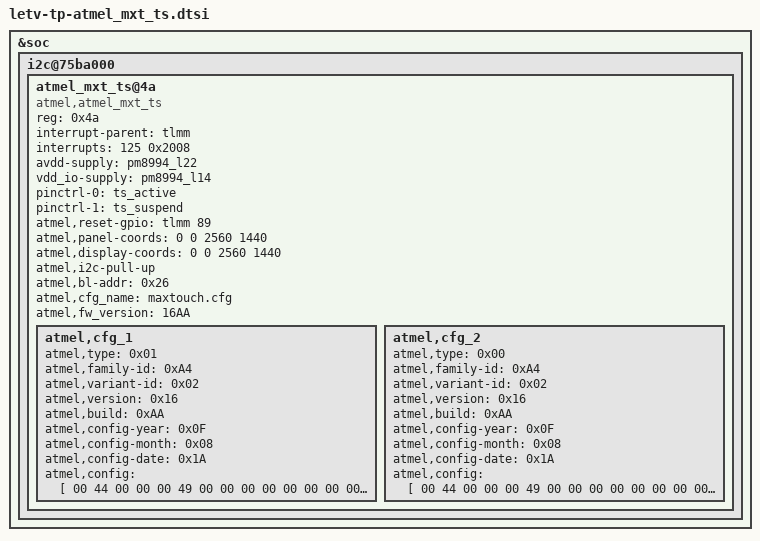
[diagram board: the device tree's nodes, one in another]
&soc {
	i2c@75ba000 {
		atmel_mxt_ts@4a {
			compatible = "atmel,atmel_mxt_ts";
			reg = <0x4a>;
			interrupt-parent = <&tlmm>;
			interrupts = <125 0x2008>;
			avdd-supply = <&pm8994_l22>;
			vdd_io-supply = <&pm8994_l14>;
			pinctrl-names = "pmx_ts_active", "pmx_ts_suspend";
			pinctrl-0 = <&ts_active>;
			pinctrl-1 = <&ts_suspend>;
			atmel,reset-gpio = <&tlmm 89 0>;
			atmel,panel-coords = <0 0 2560 1440>;
			atmel,display-coords = <0 0 2560 1440>;
			atmel,i2c-pull-up;
			atmel,bl-addr = <0x26>;
			atmel,cfg_name = "maxtouch.cfg";
			atmel,fw_version = "16AA";
			status = "ok";
			atmel,cfg_1 {
				atmel,type = <0x01>;
				atmel,family-id = <0xA4>;
				atmel,variant-id = <0x02>;
				atmel,version = <0x16>;
				atmel,build = <0xAA>;
				atmel,config-year = <0x0F>;
				atmel,config-month = <0x08>;
				atmel,config-date = <0x1A>;
				atmel,config = [
					00 44 00 00 00 49 00 00
					00 00 00 00 00 00 00 00
					00 00 00 00 00 00 00 00
					00 00 00 00 00 00 00 00
					00 00 00 00 00 00 00 00
					00 00 00 00 00 00 00 00
					00 00 00 00 00 00 00 00
					00 00 00 00 00 00 00 00
					00 00 00 00 00 00 00 00
					00 00 00 00 00 00 00
					00 26 00 00 00 40 01 16
					AA 0F 08 1A 00 00 00 00
					00 00 00 00 00 00 00 00
					00 00 00 00 00 00 00 00
					00 00 00 00 00 00 00 00
					00 00 00 00 00 00 00 00
					00 00 00 00 00 00 00 00
					00 00 00 00 00 00 00 00
					00 00 00 00 00 00
					00 47 00 00 00 C8 11 10
					01 01 01 FF 1E 00 00 00
					00 00 00 00 00 00 00 00
					00 00 00 00 00 00 00 00
					00 00 00 00 00 00 00 00
					00 00 00 00 00 00 00 00
					00 00 00 00 00 00 00 00
					00 00 00 00 00 00 00 00
					00 00 00 00 00 00 00 00
					00 00 00 00 00 00 00 00
					00 00 00 00 00 00 00 00
					00 00 00 00 00 00 00 00
					00 00 00 00 00 00 00 00
					00 00 00 00 00 00 00 00
					00 00 00 00 00 00 00 00
					00 00 00 00 00 00 00 00
					00 00 00 00 00 00 00 00
					00 00 00 00 00 00 00 00
					00 00 00 00 00 00 00 00
					00 00 00 00 00 00 00 00
					00 00 00 00 00 00 00 00
					00 00 00 00 00 00 00 00
					00 00 00 00 00 00 00 00
					00 00 00 00 00 00 00 00
					00 00 00 00 00 00 00 00
					00 00 00 00 00 00
					00 6E 00 00 00 28 01 00
					11 03 41 04 51 04 79 02
					B1 05 C1 07 81 08 31 09
					49 07 19 0B 89 0B F9 0A
					01 00 01 00 01 00 01 00
					01 00 01 00 01 00
					00 6E 00 01 00 28 01 00
					01 00 B1 03 89 06 19 07
					E1 09 C9 0D F9 0F 39 01
					F1 00 51 09 81 0B 11 0F
					01 00 01 00 01 00 01 00
					01 00 01 00 01 00
					00 6E 00 02 00 28 01 00
					01 00 01 00 01 00 01 00
					01 00 01 00 29 00 C1 02
					B1 00 31 0C F9 0F 19 0F
					01 00 01 00 01 00 01 00
					01 00 01 00 01 00
					00 6E 00 03 00 28 01 00
					11 03 41 04 51 04 79 02
					B1 05 C1 07 81 08 31 09
					49 07 19 0B 89 0B F9 0A
					01 00 01 00 01 00 01 00
					01 00 01 00 01 00
					00 6E 00 04 00 28 01 00
					01 00 B1 03 89 06 19 07
					E1 09 C9 0D F9 0F 39 01
					F1 00 51 09 81 0B 11 0F
					01 00 01 00 01 00 01 00
					01 00 01 00 01 00
					00 6E 00 05 00 28 01 00
					01 00 01 00 01 00 01 00
					01 00 01 00 29 00 C1 02
					B1 00 31 0C F9 0F 19 0F
					01 00 01 00 01 00 01 00
					01 00 01 00 01 00
					00 6E 00 06 00 28 43 03
					2B 03 2B 03 1B 03 2B 03
					13 03 03 03 F3 02 F3 02
					EB 02 E3 02 E3 02 F3 02
					03 00 03 00 03 00 03 00
					03 00 03 00 03 00
					00 6E 00 07 00 28 03 00
					CB 0F CB 0F CB 0F CB 0F
					CB 0F CB 0F CB 0F CB 0F
					CB 0F CB 0F CB 0F CB 0F
					03 00 03 00 03 00 03 00
					03 00 03 00 03 00
					00 6E 00 08 00 28 03 00
					CB 0F CB 0F CB 0F CB 0F
					CB 0F CB 0F CB 0F CB 0F
					CB 0F CB 0F CB 0F CB 0F
					03 00 03 00 03 00 03 00
					03 00 03 00 03 00
					00 07 00 00 00 05 FF FF
					19 40 00
					00 08 00 00 00 0F 8C 00
					0F 03 00 00 00 00 14 0F
					09 21 21 01 00
					00 0F 00 00 00 0B 00 1C
					10 01 03 00 05 2D 00 00
					00
					00 12 00 00 00 02 40 00
					00 13 00 00 00 06 00 00
					00 00 00 00
					00 19 00 00 00 10 00 00
					00 00 00 00 00 00 00 00
					00 00 00 00 00 00
					00 28 00 00 00 05 10 00
					00 19 19
					00 2A 00 00 00 0D 21 01
					3C 1B FF 64 00 5F 00 00
					11 03 00
					00 2B 00 00 00 12 00 00
					00 00 00 00 00 00 00 00
					00 00 00 00 00 00 00 00
					00 2E 00 00 00 0C 00 00
					10 10 00 00 00 00 00 01
					00 00
					00 2F 00 00 00 28 08 00
					23 FF 04 16 14 B9 01 18
					20 10 00 00 00 00 00 00
					00 00 00 00 80 00 80 00
					00 00 00 00 00 00 00 00
					00 00 00 00 00 00
					00 38 00 00 00 24 01 00
					01 78 0E 0D 0C 0C 0B 0A
					08 06 06 04 03 03 03 03
					02 02 02 02 02 02 02 02
					02 01 01 01 00 00 00 00
					00 00
					00 3D 00 00 00 05 01 00
					00 D0 07
					00 3D 00 01 00 05 02 00
					00 98 3A
					00 3D 00 02 00 05 02 00
					00 50 C3
					00 3D 00 03 00 05 02 00
					00 10 27
					00 3D 00 04 00 05 02 00
					00 E8 03
					00 3D 00 05 00 05 02 00
					00 10 27
					00 41 00 00 00 17 81 1E
					00 00 00 00 00 00 00 00
					0A 00 00 00 00 00 00 21
					00 00 00 00 00
					00 41 00 01 00 17 00 00
					00 00 00 00 00 00 00 00
					00 00 00 00 00 00 00 21
					00 00 00 00 00
					00 41 00 02 00 17 00 00
					00 00 00 00 00 00 00 00
					00 00 00 00 00 00 00 00
					00 00 00 00 00
					00 46 00 00 00 0A 03 26
					00 28 00 00 00 00 00 00
					00 46 00 01 00 0A 03 27
					00 28 00 00 00 01 00 00
					00 46 00 02 00 0A 01 0A
					00 3D 00 00 01 02 00 00
					00 46 00 03 00 0A 00 0D
					00 46 00 05 00 03 00 00
					00 46 00 04 00 0A 00 0D
					00 46 00 06 00 04 00 00
					00 46 00 05 00 0A 01 0D
					00 6F 00 00 15 05 00 00
					00 46 00 06 00 0A 01 0B
					00 6F 00 00 15 06 00 00
					00 46 00 07 00 0A 00 00
					00 00 00 00 00 00 00 00
					00 46 00 08 00 0A 00 00
					00 00 00 00 00 00 00 00
					00 46 00 09 00 0A 00 00
					00 00 00 00 00 00 00 00
					00 46 00 0A 00 0A 00 00
					00 00 00 00 00 00 00 00
					00 46 00 0B 00 0A 00 00
					00 00 00 00 00 00 00 00
					00 46 00 0C 00 0A 00 00
					00 00 00 00 00 00 00 00
					00 46 00 0D 00 0A 00 00
					00 00 00 00 00 00 00 00
					00 46 00 0E 00 0A 00 00
					00 00 00 00 00 00 00 00
					00 46 00 0F 00 0A 00 00
					00 00 00 00 00 00 00 00
					00 46 00 10 00 0A 00 00
					00 00 00 00 00 00 00 00
					00 46 00 11 00 0A 00 00
					00 00 00 00 00 00 00 00
					00 46 00 12 00 0A 00 00
					00 00 00 00 00 00 00 00
					00 46 00 13 00 0A 00 00
					00 00 00 00 00 00 00 00
					00 48 00 00 00 55 01 00
					00 01 00 05 0A 0A 00 06
					0C 18 02 04 20 00 0D 09
					36 05 00 01 0C 1C 27 31
					1C 1C 1C 1C 1C 1C 1C 1C
					1C 1C 00 00 16 22 01 01
					0C 1C 27 31 40 40 40 40
					40 40 40 40 40 40 00 0E
					1E 50 0F 01 0C 1C 27 31
					40 40 40 40 40 40 40 40
					40 40 00 16 00 50 00 03
					08 02 02
					00 4D 00 00 00 02 00 00
					00 4E 00 00 00 0C 84 05
					05 02 14 02 18 00 00 0F
					03 0A
					00 4F 00 00 00 04 01 0A
					00 02
					00 4F 00 01 00 04 00 00
					00 00
					00 4F 00 02 00 04 00 00
					00 00
					00 50 00 00 00 0C 08 28
					C8 1F 04 E4 03 00 00 00
					00 00
					00 51 00 00 00 12 02 00
					00 19 E6 E1 19 19 C8 E1
					19 02 FF 00 00 01 00 00
					00 51 00 01 00 12 00 00
					00 00 00 00 00 00 00 00
					00 00 00 00 00 00 00 00
					00 54 00 00 00 04 00 00
					00 00
					00 5D 00 00 00 1E 0D 3C
					00 FF FF 3C 00 FF FF FF
					0F FF 0F 00 14 00 14 04
					00 00 C8 00 C8 00 00 20
					00 20 00 00
					00 63 00 00 00 0C 00 00
					00 00 00 00 00 00 00 00
					00 00
					00 64 00 00 00 3C 83 32
					07 10 00 00 0A 88 00 18
					35 0F 0A FF 09 32 1E 32
					3C 00 0D 35 02 02 9F 05
					31 33 0A 06 37 0A 14 00
					00 37 3C 0A 00 01 01 00
					00 0A 44 FA 41 1E 00 08
					00 00 00 00 BF 19 B2 3C
					B1 32
					00 65 00 00 00 1E 00 00
					00 00 00 18 10 03 00 00
					00 00 18 0F 03 04 01 02
					FA 0A 19 00 0A 00 00 28
					00 00 00 00
					00 68 00 00 00 0B 01 09
					2D 0F 0A 03 09 2D 0F 0A
					03
					00 6C 00 00 00 4B 00 00
					00 00 00 00 00 00 00 00
					00 00 00 00 00 00 00 00
					00 00 00 00 00 00 00 00
					00 00 00 00 00 00 00 00
					00 00 00 00 00 00 00 00
					00 00 00 00 00 00 00 00
					00 00 00 00 00 00 00 00
					00 00 00 00 00 00 00 00
					00 00 00 00 00 00 00 00
					00
					00 6D 00 00 00 09 00 00
					05 00 00 00 00 00 00
					00 6F 00 00 00 17 08 00
					28 5C 28 28 08 0A 00 1E
					00 00 00 00 00 00 00 00
					00 00 33 1E 28
					00 6F 00 01 00 17 0C 00
					5F 5C 80 80 11 03 00 FF
					7F 32 11 08 0A 00 00 00
					00 00 00 00 00
					00 6F 00 02 00 17 00 00
					28 40 20 20 14 00 00 1F
					0F 22 01 01 01 00 00 00
					00 00 00 FF 00
					00 70 00 00 00 05 00 00
					00 00 00
					00 70 00 01 00 05 00 00
					00 00 00
					00 71 00 00 00 03 05 05
					05
					00 73 00 00 00 14 85 00
					00 FF FF 00 00 FF FF 35
					00 43 00 02 3E 02 00 88
					55 11
					00 74 00 00 00 FF 00 03
					03 00 D5 66 02 03 03 00
					D6 55 02 03 0C 00 D7 33
					02 13 0C 00 D8 44 02 42
					03 70 55 26 42 03 70 56
					25 12 0C 07 57 23 12 0C
					07 58 24 02 00 00 5A 22
					00 00 00 00 00 00 00 00
					00 00 00 00 00 00 00 00
					00 00 00 00 00 00 00 00
					00 00 00 00 00 00 00 00
					00 00 00 00 00 00 00 00
					00 00 00 00 00 00 00 00
					00 00 00 00 00 00 00 00
					00 00 00 00 00 00 00 00
					00 00 00 00 00 00 00 00
					00 00 00 00 00 00 00 00
					00 00 00 00 00 00 00 00
					00 00 00 00 00 00 00 00
					00 00 00 00 00 00 00 00
					00 00 00 00 00 00 00 00
					00 00 00 00 00 00 00 00
					00 00 00 00 00 00 00 00
					00 00 00 00 00 00 00 00
					00 00 00 00 00 00 00 00
					00 00 00 00 00 00 00 00
					00 00 00 00 00 00 00 00
					00 00 00 00 00 00 00 00
					00 00 00 00 00 00 00 00
					00 00 00 00 00 00 00 00
					00 00 00 00 00 00 00 00
					00 00 00 00 00 00 00 00
					00 00 00 00 00
					00 79 00 00 00 03 00 03
					00
				];
			};
			atmel,cfg_2 {
				atmel,type = <0x00>;
				atmel,family-id = <0xA4>;
				atmel,variant-id = <0x02>;
				atmel,version = <0x16>;
				atmel,build = <0xAA>;
				atmel,config-year = <0x0F>;
				atmel,config-month = <0x08>;
				atmel,config-date = <0x1A>;
				atmel,config = [
					00 44 00 00 00 49 00 00
					00 00 00 00 00 00 00 00
					00 00 00 00 00 00 00 00
					00 00 00 00 00 00 00 00
					00 00 00 00 00 00 00 00
					00 00 00 00 00 00 00 00
					00 00 00 00 00 00 00 00
					00 00 00 00 00 00 00 00
					00 00 00 00 00 00 00 00
					00 00 00 00 00 00 00
					00 26 00 00 00 40 01 16
					AA 0F 08 1A 00 00 00 00
					00 00 00 00 00 00 00 00
					00 00 00 00 00 00 00 00
					00 00 00 00 00 00 00 00
					00 00 00 00 00 00 00 00
					00 00 00 00 00 00 00 00
					00 00 00 00 00 00 00 00
					00 00 00 00 00 00
					00 47 00 00 00 C8 11 10
					01 01 01 FF 1E 00 00 00
					00 00 00 00 00 00 00 00
					00 00 00 00 00 00 00 00
					00 00 00 00 00 00 00 00
					00 00 00 00 00 00 00 00
					00 00 00 00 00 00 00 00
					00 00 00 00 00 00 00 00
					00 00 00 00 00 00 00 00
					00 00 00 00 00 00 00 00
					00 00 00 00 00 00 00 00
					00 00 00 00 00 00 00 00
					00 00 00 00 00 00 00 00
					00 00 00 00 00 00 00 00
					00 00 00 00 00 00 00 00
					00 00 00 00 00 00 00 00
					00 00 00 00 00 00 00 00
					00 00 00 00 00 00 00 00
					00 00 00 00 00 00 00 00
					00 00 00 00 00 00 00 00
					00 00 00 00 00 00 00 00
					00 00 00 00 00 00 00 00
					00 00 00 00 00 00 00 00
					00 00 00 00 00 00 00 00
					00 00 00 00 00 00 00 00
					00 00 00 00 00 00
					00 6E 00 00 00 28 01 00
					11 03 41 04 51 04 79 02
					B1 05 C1 07 81 08 31 09
					49 07 19 0B 89 0B F9 0A
					01 00 01 00 01 00 01 00
					01 00 01 00 01 00
					00 6E 00 01 00 28 01 00
					01 00 B1 03 89 06 19 07
					E1 09 C9 0D F9 0F 39 01
					F1 00 51 09 81 0B 11 0F
					01 00 01 00 01 00 01 00
					01 00 01 00 01 00
					00 6E 00 02 00 28 01 00
					01 00 01 00 01 00 01 00
					01 00 01 00 29 00 C1 02
					B1 00 31 0C F9 0F 19 0F
					01 00 01 00 01 00 01 00
					01 00 01 00 01 00
					00 6E 00 03 00 28 01 00
					11 03 41 04 51 04 79 02
					B1 05 C1 07 81 08 31 09
					49 07 19 0B 89 0B F9 0A
					01 00 01 00 01 00 01 00
					01 00 01 00 01 00
					00 6E 00 04 00 28 01 00
					01 00 B1 03 89 06 19 07
					E1 09 C9 0D F9 0F 39 01
					F1 00 51 09 81 0B 11 0F
					01 00 01 00 01 00 01 00
					01 00 01 00 01 00
					00 6E 00 05 00 28 01 00
					01 00 01 00 01 00 01 00
					01 00 01 00 29 00 C1 02
					B1 00 31 0C F9 0F 19 0F
					01 00 01 00 01 00 01 00
					01 00 01 00 01 00
					00 6E 00 06 00 28 43 03
					2B 03 2B 03 1B 03 2B 03
					13 03 03 03 F3 02 F3 02
					EB 02 E3 02 E3 02 F3 02
					03 00 03 00 03 00 03 00
					03 00 03 00 03 00
					00 6E 00 07 00 28 03 00
					CB 0F CB 0F CB 0F CB 0F
					CB 0F CB 0F CB 0F CB 0F
					CB 0F CB 0F CB 0F CB 0F
					03 00 03 00 03 00 03 00
					03 00 03 00 03 00
					00 6E 00 08 00 28 03 00
					CB 0F CB 0F CB 0F CB 0F
					CB 0F CB 0F CB 0F CB 0F
					CB 0F CB 0F CB 0F CB 0F
					03 00 03 00 03 00 03 00
					03 00 03 00 03 00
					00 07 00 00 00 05 FF FF
					19 40 00
					00 08 00 00 00 0F 8C 00
					0F 03 00 00 00 00 14 0F
					09 21 21 01 00
					00 0F 00 00 00 0B 00 1C
					10 01 03 00 05 2D 00 00
					00
					00 12 00 00 00 02 40 00
					00 13 00 00 00 06 00 00
					00 00 00 00
					00 19 00 00 00 10 00 00
					00 00 00 00 00 00 00 00
					00 00 00 00 00 00
					00 28 00 00 00 05 10 00
					00 19 19
					00 2A 00 00 00 0D 21 01
					3C 1B FF 64 00 5F 00 00
					11 03 00
					00 2B 00 00 00 12 00 00
					00 00 00 00 00 00 00 00
					00 00 00 00 00 00 00 00
					00 2E 00 00 00 0C 00 00
					10 10 00 00 00 00 00 01
					00 00
					00 2F 00 00 00 28 08 00
					23 FF 04 16 14 B9 01 18
					20 10 00 00 00 00 00 00
					00 00 00 00 80 00 80 00
					00 00 00 00 00 00 00 00
					00 00 00 00 00 00
					00 38 00 00 00 24 01 00
					01 78 0E 0D 0C 0C 0B 0A
					08 06 06 04 03 03 03 03
					02 02 02 02 02 02 02 02
					02 01 01 01 00 00 00 00
					00 00
					00 3D 00 00 00 05 01 00
					00 D0 07
					00 3D 00 01 00 05 02 00
					00 98 3A
					00 3D 00 02 00 05 02 00
					00 50 C3
					00 3D 00 03 00 05 02 00
					00 10 27
					00 3D 00 04 00 05 02 00
					00 E8 03
					00 3D 00 05 00 05 02 00
					00 10 27
					00 41 00 00 00 17 81 1E
					00 00 00 00 00 00 00 00
					0A 00 00 00 00 00 00 21
					00 00 00 00 00
					00 41 00 01 00 17 00 00
					00 00 00 00 00 00 00 00
					00 00 00 00 00 00 00 21
					00 00 00 00 00
					00 41 00 02 00 17 00 00
					00 00 00 00 00 00 00 00
					00 00 00 00 00 00 00 00
					00 00 00 00 00
					00 46 00 00 00 0A 03 26
					00 28 00 00 00 00 00 00
					00 46 00 01 00 0A 03 27
					00 28 00 00 00 01 00 00
					00 46 00 02 00 0A 01 0A
					00 3D 00 00 01 02 00 00
					00 46 00 03 00 0A 00 0D
					00 46 00 05 00 03 00 00
					00 46 00 04 00 0A 00 0D
					00 46 00 06 00 04 00 00
					00 46 00 05 00 0A 01 0D
					00 6F 00 00 15 05 00 00
					00 46 00 06 00 0A 01 0B
					00 6F 00 00 15 06 00 00
					00 46 00 07 00 0A 00 00
					00 00 00 00 00 00 00 00
					00 46 00 08 00 0A 00 00
					00 00 00 00 00 00 00 00
					00 46 00 09 00 0A 00 00
					00 00 00 00 00 00 00 00
					00 46 00 0A 00 0A 00 00
					00 00 00 00 00 00 00 00
					00 46 00 0B 00 0A 00 00
					00 00 00 00 00 00 00 00
					00 46 00 0C 00 0A 00 00
					00 00 00 00 00 00 00 00
					00 46 00 0D 00 0A 00 00
					00 00 00 00 00 00 00 00
					00 46 00 0E 00 0A 00 00
					00 00 00 00 00 00 00 00
					00 46 00 0F 00 0A 00 00
					00 00 00 00 00 00 00 00
					00 46 00 10 00 0A 00 00
					00 00 00 00 00 00 00 00
					00 46 00 11 00 0A 00 00
					00 00 00 00 00 00 00 00
					00 46 00 12 00 0A 00 00
					00 00 00 00 00 00 00 00
					00 46 00 13 00 0A 00 00
					00 00 00 00 00 00 00 00
					00 48 00 00 00 55 01 00
					00 01 00 05 0A 0A 00 06
					0C 18 02 04 20 00 0D 09
					36 05 00 01 0C 1C 27 31
					1C 1C 1C 1C 1C 1C 1C 1C
					1C 1C 00 00 16 22 01 01
					0C 1C 27 31 40 40 40 40
					40 40 40 40 40 40 00 0E
					1E 50 0F 01 0C 1C 27 31
					40 40 40 40 40 40 40 40
					40 40 00 16 00 50 00 03
					08 02 02
					00 4D 00 00 00 02 00 00
					00 4E 00 00 00 0C 84 05
					05 02 14 02 18 00 00 0F
					03 0A
					00 4F 00 00 00 04 01 0A
					00 02
					00 4F 00 01 00 04 00 00
					00 00
					00 4F 00 02 00 04 00 00
					00 00
					00 50 00 00 00 0C 08 28
					C8 1F 04 E4 03 00 00 00
					00 00
					00 51 00 00 00 12 02 00
					00 19 E6 E1 19 19 C8 E1
					19 02 FF 00 00 01 00 00
					00 51 00 01 00 12 00 00
					00 00 00 00 00 00 00 00
					00 00 00 00 00 00 00 00
					00 54 00 00 00 04 00 00
					00 00
					00 5D 00 00 00 1E 0D 3C
					00 FF FF 3C 00 FF FF FF
					0F FF 0F 00 14 00 14 04
					00 00 C8 00 C8 00 00 20
					00 20 00 00
					00 63 00 00 00 0C 00 00
					00 00 00 00 00 00 00 00
					00 00
					00 64 00 00 00 3C 83 32
					07 10 00 00 0A 88 00 18
					35 0F 0A FF 09 32 1E 32
					3C 00 0D 35 02 02 9F 05
					31 33 0A 06 37 0A 14 00
					00 37 3C 0A 00 01 01 00
					00 0A 44 FA 41 1E 00 08
					00 00 00 00 BF 19 B2 3C
					B1 32
					00 65 00 00 00 1E 00 00
					00 00 00 18 10 03 00 00
					00 00 18 0F 03 04 01 02
					FA 0A 19 00 0A 00 00 28
					00 00 00 00
					00 68 00 00 00 0B 01 09
					2D 0F 0A 03 09 2D 0F 0A
					03
					00 6C 00 00 00 4B 00 00
					00 00 00 00 00 00 00 00
					00 00 00 00 00 00 00 00
					00 00 00 00 00 00 00 00
					00 00 00 00 00 00 00 00
					00 00 00 00 00 00 00 00
					00 00 00 00 00 00 00 00
					00 00 00 00 00 00 00 00
					00 00 00 00 00 00 00 00
					00 00 00 00 00 00 00 00
					00
					00 6D 00 00 00 09 00 00
					05 00 00 00 00 00 00
					00 6F 00 00 00 17 08 00
					28 5C 28 28 08 0A 00 1E
					00 00 00 00 00 00 00 00
					00 00 33 1E 28
					00 6F 00 01 00 17 0C 00
					5F 5C 80 80 11 03 00 FF
					7F 32 11 08 0A 00 00 00
					00 00 00 00 00
					00 6F 00 02 00 17 00 00
					28 40 20 20 14 00 00 1F
					0F 22 01 01 01 00 00 00
					00 00 00 FF 00
					00 70 00 00 00 05 00 00
					00 00 00
					00 70 00 01 00 05 00 00
					00 00 00
					00 71 00 00 00 03 05 05
					05
					00 73 00 00 00 14 85 00
					00 FF FF 00 00 FF FF 35
					00 43 00 02 3E 02 00 88
					55 11
					00 74 00 00 00 FF 00 03
					03 00 D5 66 02 03 03 00
					D6 55 02 03 0C 00 D7 33
					02 13 0C 00 D8 44 02 42
					03 70 55 26 42 03 70 56
					25 12 0C 07 57 23 12 0C
					07 58 24 02 00 00 5A 22
					00 00 00 00 00 00 00 00
					00 00 00 00 00 00 00 00
					00 00 00 00 00 00 00 00
					00 00 00 00 00 00 00 00
					00 00 00 00 00 00 00 00
					00 00 00 00 00 00 00 00
					00 00 00 00 00 00 00 00
					00 00 00 00 00 00 00 00
					00 00 00 00 00 00 00 00
					00 00 00 00 00 00 00 00
					00 00 00 00 00 00 00 00
					00 00 00 00 00 00 00 00
					00 00 00 00 00 00 00 00
					00 00 00 00 00 00 00 00
					00 00 00 00 00 00 00 00
					00 00 00 00 00 00 00 00
					00 00 00 00 00 00 00 00
					00 00 00 00 00 00 00 00
					00 00 00 00 00 00 00 00
					00 00 00 00 00 00 00 00
					00 00 00 00 00 00 00 00
					00 00 00 00 00 00 00 00
					00 00 00 00 00 00 00 00
					00 00 00 00 00 00 00 00
					00 00 00 00 00 00 00 00
					00 00 00 00 00
					00 79 00 00 00 03 00 03
					00
				];
			};
		};
	};
};
